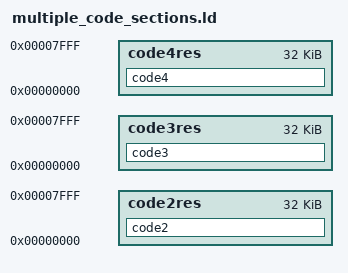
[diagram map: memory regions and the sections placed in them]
/* DO NOT EDIT!
   This file was automatically generated by m68k-palmos-multigen v2.3
   from ../DateBook.def  */

MEMORY
{
	code2res : ORIGIN = 0x0, LENGTH = 32768
	code3res : ORIGIN = 0x0, LENGTH = 32768
	code4res : ORIGIN = 0x0, LENGTH = 32768
}

SECTIONS
{
	code2 : { *(code2) } > code2res
	code3 : { *(code3) } > code3res
	code4 : { *(code4) } > code4res
}
